# SPC1068 register map
File version: 20180100_70611510
Information about Spc1068
CPU: CM3 r2p1, little endian, MPU, no FPU, 4 interrupt priority bits
Registers are 32-bit, read-write, reset 0x0 unless marked. A register's access mark holds for its fields unless they carry their own. Offsets are from the block's base; lines under a group give offsets from that group; [hi:lo] are bit positions; {n}, {i} and the like mark numbered series; 'fields as' and 'values as' point back to an identical list; <NAME> marks a mode.

## Memory map
0x40000000 WDT1 size 0x24 — Watchdog 1
0x40001000 TIMER0 size 0x10 — NOEN
0x40002000 TIMER1 size 0x10
0x40003000 GPIO size 0xA4 — General purpose input and output
0x40004000 UART size 0x30 — NOEN
0x40005000 SSP size 0x3C — NOEN
0x40006000 I2C size 0xA0
0x40007000 PWM0 size 0x9C — NOEN
0x40007100 PWM1 size 0x9C
0x40007200 PWM2 size 0x9C
0x40007300 PWM3 size 0x9C
0x40007400 PWM4 size 0x9C
0x40007500 PWM5 size 0x9C
0x40007600 PWM6 size 0x9C
0x40008000 WDT0 size 0x24
0x40009000 QSPI size 0x3C — NOEN
0x4000A000 PGA size 0x108 — Split from ADC
0x4000A000 COMP size 0x108 — Split from ADC
0x4000A000 ADC size 0x108 — Analog Digital converter
0x4000B000 CLOCK size 0x174 — Split from GLOBAL
0x4000B000 GLOBAL size 0x174
0x4000B000 POWER size 0x174 — Split from GLOBAL
0x4000B000 PINMUX size 0x174 — Split from GLOBAL
0x4000C000 TIMER2 size 0x10
0x4000D000 ECAP size 0x24
0x41000000 CRC size 0x20 — NOEN
0x41000400 AES size 0x6C

## Interrupts
0 UART
1 I2C
2 SSP
4 QSPI
5 ECAP
7 PWM0
12 WDT1
21 PWM1
23 PWM2
25 PWM3
27 PWM4
29 PWM5
31 PWM6
34 AES
35 CRC
37 CLOCK

## WDT1 — Watchdog 1
Base 0x40000000
Same registers: WDT0 0x40008000
0x00 WDTLOAD reset 0xFFFFFFFF — Watchdog Timer Load Register
  [31:0] VAL — Load value. The value from which the counter is to decrease. When this register is written to, the count is immediately restarted from the new value. The minimum valid value is 1.
0x04 WDTCNT ro reset 0xFFFFFFFF — Watchdog Timer Current Value Register
  [31:0] VAL — Current value of the decrementing counter
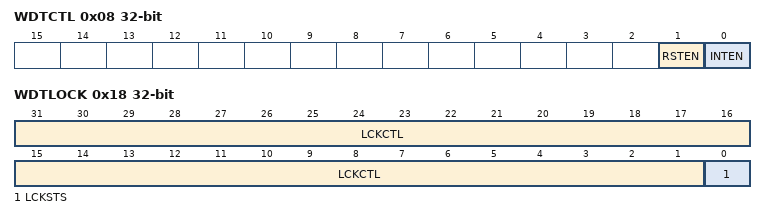
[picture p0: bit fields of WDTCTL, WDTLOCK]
0x08 WDTCTL — Watchdog Timer Control Register
  [1] RSTEN — Enable watchdog reset output, Acts as a mask for the reset output
    0=DISABLE (Disable the reset request); 1=ENABLE (Enable the reset request)
  [0] INTEN — Enable the interrupt event. Reloads the counter from WDTLOAD when the interrupt upon a rising edge of this bit.
    0=DISABLE (Disable the counter and the interrupt); 1=ENABLE (Enable the counter and the interrupt)
0x0C WDTIC wo — Watchdog Timer Clear Interrupt Register
  [31:0] VAL — Interrupt clear register. A write of any value to this register clears the watchdog interrupt, and reloads the counter from WDTLOAD.
0x10 WDTRAWIF reset 0x4 — Watchdog Timer Raw Interrupt Status Register
  [0] RAWINT ro — Raw interrupt status from the counter. This register indicates the raw interrupt status from the counter. The value is ANDed with WDTCTL.INTEN to create the masked interrupt, which is passed to the interrupt output pin.
    0=NOT_OCCUR (Interrupt not occurred); 1=OCCUR (Interrupt occurred)
0x14 WDTIF ro — Watchdog Timer Interrupt Status Register
  [0] INT — Masked interrupt status from the counter. This register indicates the masked interrupt status from the counter. This value is the logical AND of WDTRAWIF.RAWINT and WDTCTL.INTEN, and is the same value that is passed to the interrupt output pin.
    values as WDTRAWIF.RAWINT
0x18 WDTLOCK — Watchdog Timer Lock Register
  [31:1] LCKCTL — Enable register writes. Enable write access to all other registers by writing 0x1ACCE551. Disable write access by writing any other value.
  [0] LCKSTS ro — Register write lock status
    0=UNLOCK (Write access to all other registers is enabled (not locked)); 1=LOCK (Write access to all other registers is disabled (locked))

## Licence text in the file
ARM Limited (ARM) is supplying this software for use with Cortex-M processor based microcontroller, but can be equally used for other suitable processor architectures. This file can be freely distributed. Modifications to this file shall be clearly marked. . THIS SOFTWARE IS PROVIDED "AS IS". NO WARRANTIES, WHETHER EXPRESS, IMPLIED. OR STATUTORY, INCLUDING, BUT NOT LIMITED TO, IMPLIED WARRANTIES OF. MERCHANTABILITY AND FITNESS FOR A PARTICULAR PURPOSE APPLY TO THIS SOFTWARE. ARM SHALL NOT, IN ANY CIRCUMSTANCES, BE LIABLE FOR SPECIAL, INCIDENTAL, OR. CONSEQUENTIAL DAMAGES, FOR ANY REASON WHATSOEVER.

## Notices in the file
Copyright (C) 2014-2020 ARM Limited. All rights reserved.
Purpose: System Viewer Description (SVD) Example (Schema Version 1.1)
This is a description of a none-existent and incomplete device
for demonstration purposes only.
Redistribution and use in source and binary forms, with or without
modification, are permitted provided that the following conditions are met:
- Redistributions of source code must retain the above copyright
notice, this list of conditions and the following disclaimer.
- Redistributions in binary form must reproduce the above copyright
notice, this list of conditions and the following disclaimer in the
documentation and/or other materials provided with the distribution.
- Neither the name of ARM nor the names of its contributors may be used
to endorse or promote products derived from this software without
specific prior written permission.
THIS SOFTWARE IS PROVIDED BY THE COPYRIGHT HOLDERS AND CONTRIBUTORS "AS IS"
AND ANY EXPRESS OR IMPLIED WARRANTIES, INCLUDING, BUT NOT LIMITED TO, THE
ARE DISCLAIMED. IN NO EVENT SHALL COPYRIGHT HOLDERS AND CONTRIBUTORS BE
LIABLE FOR ANY DIRECT, INDIRECT, INCIDENTAL, SPECIAL, EXEMPLARY, OR
CONSEQUENTIAL DAMAGES (INCLUDING, BUT NOT LIMITED TO, PROCUREMENT OF
SUBSTITUTE GOODS OR SERVICES; LOSS OF USE, DATA, OR PROFITS; OR BUSINESS
INTERRUPTION) HOWEVER CAUSED AND ON ANY THEORY OF LIABILITY, WHETHER IN
CONTRACT, STRICT LIABILITY, OR TORT (INCLUDING NEGLIGENCE OR OTHERWISE)
ARISING IN ANY WAY OUT OF THE USE OF THIS SOFTWARE, EVEN IF ADVISED OF THE
POSSIBILITY OF SUCH DAMAGE.
